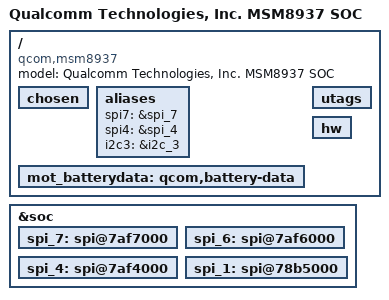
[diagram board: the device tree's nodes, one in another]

/* Copyright (c) 2018, The Linux Foundation. All rights reserved.
 *
 * This program is free software; you can redistribute it and/or modify
 * it under the terms of the GNU General Public License version 2 and
 * only version 2 as published by the Free Software Foundation.
 *
 * This program is distributed in the hope that it will be useful,
 * but WITHOUT ANY WARRANTY; without even the implied warranty of
 * MERCHANTABILITY or FITNESS FOR A PARTICULAR PURPOSE.  See the
 * GNU General Public License for more details.
 */

#include "msm8937.dtsi"
#include "pmi8950.dtsi"

&soc {
	spi_7: spi@7af7000 { };
	spi_6: spi@7af6000 { };
	spi_4: spi@7af4000 { };
	spi_1: spi@78b5000 { };

};

/ {
	model = "Qualcomm Technologies, Inc. MSM8937 SOC";
	compatible = "qcom,msm8937";

	chosen: chosen { };
	aliases: aliases {
		spi7 = &spi_7;
		spi4 = &spi_4;
		i2c3 = &i2c_3;
	};
	mot_batterydata: qcom,battery-data {};
	utags: utags {};
	hw: hw {};
};
